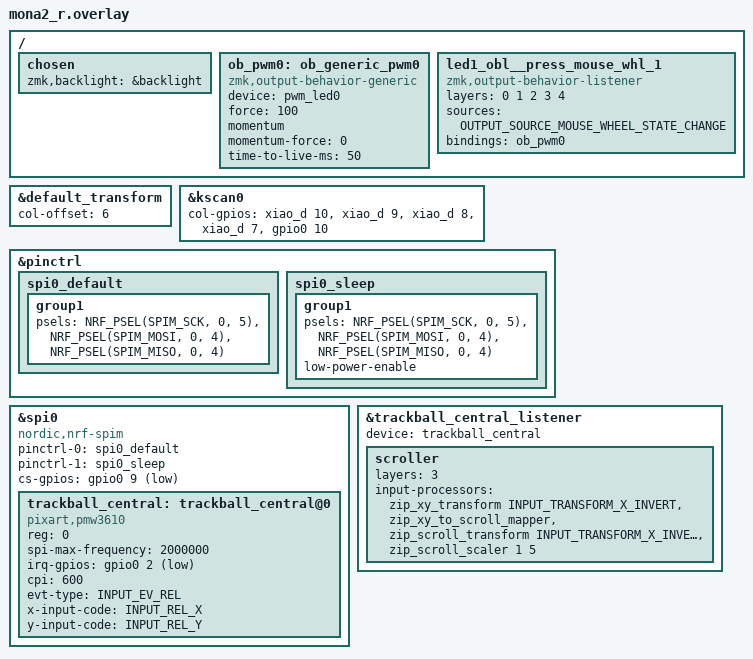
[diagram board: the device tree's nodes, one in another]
#include "mona2.dtsi"
#include <input/processors.dtsi>
#include <zephyr/dt-bindings/input/input-event-codes.h>

// #include <>

/* enums to set in sources to filter events in zmk,output-behavior-listener */
#define OUTPUT_SOURCE_LAYER_STATE_CHANGE        1
#define OUTPUT_SOURCE_POSITION_STATE_CHANGE     2
#define OUTPUT_SOURCE_KEYCODE_STATE_CHANGE      3
#define OUTPUT_SOURCE_MOUSE_BUTTON_STATE_CHANGE 4
#define OUTPUT_SOURCE_MOUSE_WHEEL_STATE_CHANGE  5
#define OUTPUT_SOURCE_TRANSPORT                 6

/{
    chosen {
        zmk,backlight = &backlight;
    };

    /* setup behavior for PWM device */
    ob_pwm0: ob_generic_pwm0 {
            compatible = "zmk,output-behavior-generic";
            #binding-cells = <0>;
            device = <&pwm_led0>;
            
            /* set duty cycle of pwm, max 256 */
            /* pwm duty cycle raise to <180> on key press */
            force = <100>;

            /* enable momentum to trigger on both on all state change */
            momentum;

            /* pwm duty cycle drop to <12> on key release */
            momentum-force = <0>;

            time-to-live-ms = <50>;
    };

    /* setup listener on mouse wheel input, and feedback via ERM */
    /* usually, no feedback from scrolling on touchpad or trackball, this config adds haptic feedback to emulate notchy bump from physical scroll wheel */
    led1_obl__press_mouse_whl_1 {
            compatible = "zmk,output-behavior-listener";
            layers = < 0 1 2 3 4 >;
            /* trigger on mouse wheel status change */
            sources = < OUTPUT_SOURCE_MOUSE_WHEEL_STATE_CHANGE >;
            bindings = < &ob_pwm0 >;

            // all-state;
    };
};

&default_transform {
    col-offset = <6>;
};

&kscan0 {
        col-gpios
            = <&xiao_d 10 GPIO_ACTIVE_HIGH>
            , <&xiao_d 9 GPIO_ACTIVE_HIGH> 
            , <&xiao_d 8 GPIO_ACTIVE_HIGH> 
            , <&xiao_d 7 GPIO_ACTIVE_HIGH> 
            , <&gpio0 10 GPIO_ACTIVE_HIGH>
            ;
};


&pinctrl {
    spi0_default: spi0_default {    //通常時(SPI通信中)のピン構成
        group1 {
            psels = <NRF_PSEL(SPIM_SCK, 0, 5)>, //P0.05を指定(SCLK)
                <NRF_PSEL(SPIM_MOSI, 0, 4)>,    //P0.04を指定(SDIOだからMOSI,MISO両方の役割を担う)
                <NRF_PSEL(SPIM_MISO, 0, 4)>;
        };
    };

    spi0_sleep: spi0_sleep {    //スリープ時のピン構成(省電力)
        group1 {
            psels = <NRF_PSEL(SPIM_SCK, 0, 5)>,
                <NRF_PSEL(SPIM_MOSI, 0, 4)>,
                <NRF_PSEL(SPIM_MISO, 0, 4)>;
            low-power-enable;
        };
    };
};


&spi0 {
    status = "okay";
    compatible = "nordic,nrf-spim"; //マイコンがnRFシリーズ
    pinctrl-0 = <&spi0_default>;
    pinctrl-1 = <&spi0_sleep>;
    pinctrl-names = "default", "sleep";
    cs-gpios = <&gpio0 9 GPIO_ACTIVE_LOW>;  //P0.09を指定(CS)

    trackball_central: trackball_central@0 {
        status = "okay";
        compatible = "pixart,pmw3610";  //トラボセンサ用のドライバとバインド
        reg = <0>;
        spi-max-frequency = <2000000>;
        irq-gpios = <&gpio0 2 (GPIO_ACTIVE_LOW | GPIO_PULL_UP)>; //P0.02を指定(MOTION)
        cpi = <600>;
        //swap-xy;
        //invert-x; //COROPIT版ではコメントアウトを外す
        //invert-y; //COROPIT版ではコメントアウトを外す
        evt-type = <INPUT_EV_REL>;
        x-input-code = <INPUT_REL_X>;
        y-input-code = <INPUT_REL_Y>;
    };
};


// Overrides for the input listener node
&trackball_central_listener {
    status = "okay";
    device = <&trackball_central>;

    scroller {
        layers = <3>;
        input-processors = 
            // <&zip_xy_transform INPUT_TRANSFORM_XY_SWAP>,        //X軸とY軸の入れ替え
            <&zip_xy_transform INPUT_TRANSFORM_X_INVERT>,       //X軸反転
            <&zip_xy_to_scroll_mapper>,                         //スクロールモードに変更
            <&zip_scroll_transform INPUT_TRANSFORM_X_INVERT>,   //スクロールのX軸反転
            <&zip_scroll_scaler 1 5>;                           //スクロール量を1/4倍
    };

};
